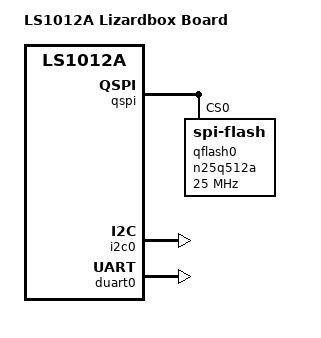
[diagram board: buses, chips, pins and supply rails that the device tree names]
/*
 * Device Tree file for Freescale Layerscape-1012A family SoC.
 *
 * Copyright 2016, Freescale Semiconductor
 *
 * SPDX-License-Identifier:	GPL-2.0+
 */

/include/ "fsl-ls1012a.dtsi"

/ {
	model = "LS1012A Lizardbox Board";
	aliases {
		spi0 = &qspi;
	};
};

&qspi {
	bus-num = <0>;
	status = "okay";

	qflash0: n25q512a@0 {
		#address-cells = <1>;
		#size-cells = <1>;
		compatible = "spi-flash";
		spi-max-frequency = <25000000>;
		reg = <0>;
	};
};

&i2c0 {
	status = "okay";
};

&duart0 {
	status = "okay";
};
